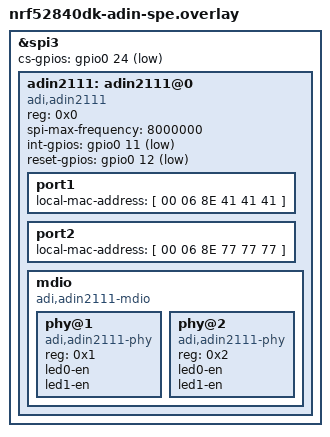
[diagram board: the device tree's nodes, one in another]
/*
 * Adds ADIN1110 SPE Support to Nordic nRF52840-DK on SPI3
 *
 * SPE Interface Pins as follows:- 
 * SCK  P1.15
 * MOSI P1.13
 * MISO P1.14
 * CS   P0.24
 * IRQ  P0.11
 * RST  P0.12
 *
 * Note - If using EVAL-ADIN1110EBZ,
 * J310 = GND
 * J204, VDDIO = 1.8V
 */


&spi3 {
   status = "okay";
   cs-gpios = <&gpio0 24 GPIO_ACTIVE_LOW>;




   adin2111: adin2111@0 {
          compatible = "adi,adin2111";
          status = "okay";
        
          reg = <0x0>;
          spi-max-frequency = <8000000>;
          int-gpios   = <&gpio0 11 (GPIO_ACTIVE_LOW | GPIO_PULL_UP)>;
          reset-gpios = <&gpio0 12 GPIO_ACTIVE_LOW>;
	
          port1 {
             local-mac-address = [ 00 06 8E 41 41 41 ];
          };

          port2 {
             local-mac-address = [ 00 06 8E 77 77 77 ];
             
          };
          
          mdio: mdio {
                  compatible = "adi,adin2111-mdio";
                  
                  status = "okay";
                  #address-cells = <1>;
                  #size-cells = <0>;
                  phy@1 {
                    reg = <0x1>;
                    compatible = "adi,adin2111-phy";
                    status = "okay";
                    led0-en;
                    led1-en;
                    
                  };
                  
                  phy@2 {
                    reg = <0x2>;
                    compatible = "adi,adin2111-phy";
                    status = "okay";
                    led0-en;
                    led1-en;
                  };
          };
  };
};



